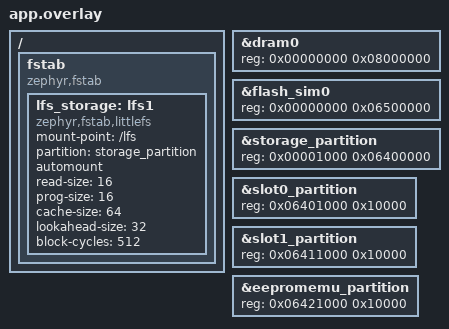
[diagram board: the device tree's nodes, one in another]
/*
 * otto Zephyr test-bed devicetree overlay — LittleFS on flash simulator
 * (Zephyr 2.7).
 *
 * Identical in shape to v3_7_lfs/app.overlay. The qemu_x86 board's stock
 * `storage_partition` exists in 2.7 with the same labels (slot0/slot1/
 * eepromemu) — the property-override pattern below applies unchanged.
 *
 * NOTE: binding parity with 3.7 is the expectation, not a proof — confirm
 * with a real `west build` on first provision.
 */

&dram0 {
	reg = <0x00000000 0x08000000>;   /* 128 MiB */
};

&flash_sim0 {
	reg = <0x00000000 0x06500000>;   /* 101 MiB total. */
};

&storage_partition {
	reg = <0x00001000 0x06400000>;   /* 100 MiB at offset 4 KiB. */
};

&slot0_partition {
	reg = <0x06401000 0x10000>;
};
&slot1_partition {
	reg = <0x06411000 0x10000>;
};
&eepromemu_partition {
	reg = <0x06421000 0x10000>;
};

/ {
	fstab {
		compatible = "zephyr,fstab";
		lfs_storage: lfs1 {
			compatible = "zephyr,fstab,littlefs";
			mount-point = "/lfs";
			partition = <&storage_partition>;
			automount;
			read-size = <16>;
			prog-size = <16>;
			cache-size = <64>;
			lookahead-size = <32>;
			block-cycles = <512>;
		};
	};
};
